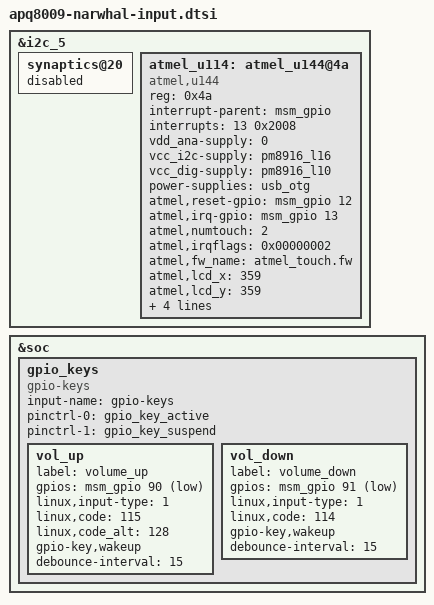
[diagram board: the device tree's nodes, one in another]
/* Copyright (c) 2017, LGE Inc. All rights reserved.
 *
 * This program is free software; you can redistribute it and/or modify
 * it under the terms of the GNU General Public License version 2 and
 * only version 2 as published by the Free Software Foundation.
 *
 * This program is distributed in the hope that it will be useful,
 * but WITHOUT ANY WARRANTY; without even the implied warranty of
 * MERCHANTABILITY or FITNESS FOR A PARTICULAR PURPOSE.  See the
 * GNU General Public License for more details.
 */

&i2c_5 { /* i2c@78b9000 */
	synaptics@20 {
		status = "disabled";
	};

	atmel_u114: atmel_u144@4a {
		compatible = "atmel,u144";
		status = "okay";
		reg = <0x4a>;
		interrupt-parent = <&msm_gpio>;
		interrupts = <13 0x2008>;
		vdd_ana-supply = <0>;
		vcc_i2c-supply = <&pm8916_l16>;
		vcc_dig-supply = <&pm8916_l10>;
		power-supplies = <&usb_otg>;
		atmel,reset-gpio = <&msm_gpio 12 0x00>;
		atmel,irq-gpio = <&msm_gpio 13 0x2008>;
		atmel,numtouch = <2>; /*multi-touch count*/
		atmel,irqflags = <0x00000002>;
		atmel,fw_name = "atmel_touch.fw";
		atmel,lcd_x = <359>;
		atmel,lcd_y = <359>;
		atmel,palm-enabled;
		atmel,wakeup;

		pinctrl-names = "pmx_ts_active","pmx_ts_suspend";
		pinctrl-0 = <&ts_int_active &ts_reset_active>;
		pinctrl-1 = <&ts_int_suspend &ts_reset_suspend>;
	};
};

&soc {
	gpio_keys {
		compatible = "gpio-keys";
		input-name = "gpio-keys";
		pinctrl-names = "tlmm_gpio_key_active","tlmm_gpio_key_suspend";
		pinctrl-0 = <&gpio_key_active>;
		pinctrl-1 = <&gpio_key_suspend>;

		vol_up {
			label = "volume_up";
			gpios = <&msm_gpio 90 0x1>;
			linux,input-type = <1>;
			linux,code = <115>;
			linux,code_alt = <128>;
			gpio-key,wakeup;
			debounce-interval = <15>;
		};

		vol_down {
			label = "volume_down";
			gpios = <&msm_gpio 91 0x1>;
			linux,input-type = <1>;
			linux,code = <114>;
			gpio-key,wakeup;
			debounce-interval = <15>;
		};
	};
};
